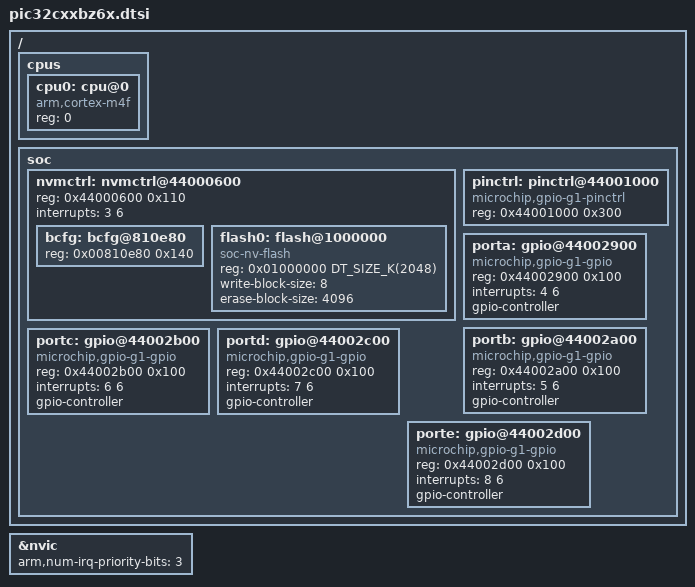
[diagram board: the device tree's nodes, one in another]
/*
 * SPDX-FileCopyrightText: Copyright (c) 2026 Microchip Technology Inc.
 *
 * SPDX-License-Identifier: Apache-2.0
 */

#include <arm/armv7-m.dtsi>
#include <zephyr/dt-bindings/gpio/gpio.h>

/ {
	cpus {
		#address-cells = <1>;
		#size-cells = <0>;

		cpu0: cpu@0 {
			compatible = "arm,cortex-m4f";
			reg = <0>;
			device_type = "cpu";
			#address-cells = <1>;
			#size-cells = <1>;
		};
	};

	soc {
		nvmctrl: nvmctrl@44000600 {
			reg = <0x44000600 0x110>;
			interrupts = <3 6>;
			#address-cells = <1>;
			#size-cells = <1>;

			bcfg: bcfg@810e80 {
				reg = <0x00810e80 0x140>;
			};

			flash0: flash@1000000 {
				compatible = "soc-nv-flash";
				reg = <0x01000000 DT_SIZE_K(2048)>;
				write-block-size = <8>;
				erase-block-size = <4096>;
			};
		};

		pinctrl: pinctrl@44001000 {
			compatible = "microchip,gpio-g1-pinctrl";
			reg = <0x44001000 0x300>;
			#address-cells = <1>;
			status = "okay";
		};

		porta: gpio@44002900 {
			compatible = "microchip,gpio-g1-gpio";
			reg = <0x44002900 0x100>;
			interrupts = <4 6>;
			gpio-controller;
			#gpio-cells = <2>;
		};

		portb: gpio@44002a00 {
			compatible = "microchip,gpio-g1-gpio";
			reg = <0x44002a00 0x100>;
			interrupts = <5 6>;
			gpio-controller;
			#gpio-cells = <2>;
		};

		portc: gpio@44002b00 {
			compatible = "microchip,gpio-g1-gpio";
			reg = <0x44002b00 0x100>;
			interrupts = <6 6>;
			gpio-controller;
			#gpio-cells = <2>;
		};

		portd: gpio@44002c00 {
			compatible = "microchip,gpio-g1-gpio";
			reg = <0x44002c00 0x100>;
			interrupts = <7 6>;
			gpio-controller;
			#gpio-cells = <2>;
		};

		porte: gpio@44002d00 {
			compatible = "microchip,gpio-g1-gpio";
			reg = <0x44002d00 0x100>;
			interrupts = <8 6>;
			gpio-controller;
			#gpio-cells = <2>;
		};
	};
};

&nvic {
	arm,num-irq-priority-bits = <3>;
};
